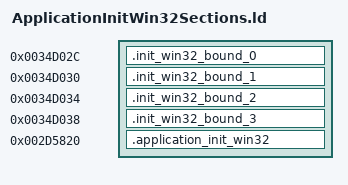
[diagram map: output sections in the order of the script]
SECTIONS
{
    .init_win32_bound_0 0x0034d02c : { *application-helpers.o(.text._ZNK16TouchScreenWin3212getLeftBoundEv .gnu.linkonce.t._ZNK16TouchScreenWin3212getLeftBoundEv) }
    .init_win32_bound_1 0x0034d030 : { *application-helpers.o(.text._ZNK16TouchScreenWin3213getRightBoundEv .gnu.linkonce.t._ZNK16TouchScreenWin3213getRightBoundEv) }
    .init_win32_bound_2 0x0034d034 : { *application-helpers.o(.text._ZNK16TouchScreenWin3211getTopBoundEv .gnu.linkonce.t._ZNK16TouchScreenWin3211getTopBoundEv) }
    .init_win32_bound_3 0x0034d038 : { *application-helpers.o(.text._ZNK16TouchScreenWin3214getBottomBoundEv .gnu.linkonce.t._ZNK16TouchScreenWin3214getBottomBoundEv) }
    .application_init_win32 0x002d5820 : { *application-helpers.o(.text._ZN11Application9InitWin32EPN3irr14IrrlichtDeviceE) }
}
